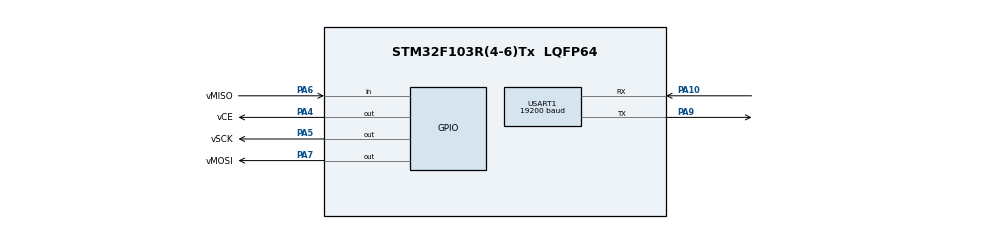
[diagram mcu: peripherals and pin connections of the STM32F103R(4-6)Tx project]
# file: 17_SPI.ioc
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Mcu.Family=STM32F1
Mcu.Name=STM32F103R(4-6)Tx
Mcu.Package=LQFP64
NVIC.PriorityGroup=NVIC_PRIORITYGROUP_4
NVIC.USART1_IRQn=true\:0\:0\:false\:false\:true\:true\:true\:true
PA10.Mode=Asynchronous
PA10.Signal=USART1_RX
PA4.GPIO_Label=vCE
PA4.GPIO_ModeDefaultOutputPP=GPIO_MODE_OUTPUT_PP
PA4.GPIO_PuPd=GPIO_PULLDOWN
PA4.Signal=GPIO_Output
PA5.GPIO_Label=vSCK
PA5.GPIO_ModeDefaultOutputPP=GPIO_MODE_OUTPUT_OD
PA5.GPIO_PuPd=GPIO_PULLUP
PA5.GPIO_Speed=GPIO_SPEED_FREQ_HIGH
PA5.PinState=GPIO_PIN_SET
PA5.Signal=GPIO_Output
PA6.GPIO_Label=vMISO
PA6.GPIO_Mode=GPIO_MODE_INPUT
PA6.GPIO_PuPd=GPIO_PULLUP
PA6.Signal=GPIO_Input
PA7.GPIO_Label=vMOSI
PA7.GPIO_ModeDefaultOutputPP=GPIO_MODE_OUTPUT_OD
PA7.GPIO_PuPd=GPIO_PULLUP
PA7.GPIO_Speed=GPIO_SPEED_FREQ_HIGH
PA7.PinState=GPIO_PIN_SET
PA7.Signal=GPIO_Output
PA9.Mode=Asynchronous
PA9.Signal=USART1_TX
ProjectManager.HeapSize=0x200
ProjectManager.StackSize=0x400
ProjectManager.TargetToolchain=MDK-ARM V5.32
RCC.APB1Freq_Value=8000000
RCC.APB2Freq_Value=8000000
USART1.BaudRate=19200
USART1.VirtualMode=VM_ASYNC
VP_SYS_VS_ND.Mode=No_Debug
board=custom

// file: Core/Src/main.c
/* USER CODE BEGIN Header */
/**
  ******************************************************************************
  * @file           : main.c
  * @brief          : Main program body
  ******************************************************************************
  * @attention
  *
  * Copyright (c) 2022 STMicroelectronics.
  * All rights reserved.
  *
  * This software is licensed under terms that can be found in the LICENSE file
  * in the root directory of this software component.
  * If no LICENSE file comes with this software, it is provided AS-IS.
  *
  ******************************************************************************
  */
/* USER CODE END Header */
#include "main.h"
#include "usart.h"
#include "gpio.h"

/* USER CODE BEGIN Includes */
#include "stdio.h"	//引入输入输出标准库
#include "vSPI.h"		//引入自定义头文件
#include "TC72.h"
/* USER CODE END Includes */

void SystemClock_Config(void);

int main(void)
{
  /* USER CODE BEGIN 1 */
	float t;
	char str1[] = "Temperature:";
	char str2[10];		//存放温度字符串
  /* USER CODE END 1 */

  /* MCU Configuration--------------------------------------------------------*/

  /* Reset of all peripherals, Initializes the Flash interface and the Systick. */
  HAL_Init();

  /* Configure the system clock */
  SystemClock_Config();

  /* Initialize all configured peripherals */
  MX_GPIO_Init();
  MX_USART1_UART_Init();

  /* Infinite loop */
  /* USER CODE BEGIN WHILE */
  while (1)
  {
		HAL_UART_Transmit(&huart1, (uint8_t *)str1, 12, 12);		//串口发送str1
		TC72_Convert(_TC72_OnceCnv);		//单次转化指令
		HAL_Delay(100);
		t = TC72_TemperatureRd();		//读传感器温度
		sprintf(str2, "%f", t);		//将温度t由浮点型转化为字符串并存入数组str2
		HAL_UART_Transmit(&huart1, (uint8_t *)str2, 7, 7);		//串口发送str2
		HAL_UART_Transmit(&huart1, (uint8_t *)&"\n\r", 2, 2);
		HAL_Delay(900);
    /* USER CODE END WHILE */

  }
}

void SystemClock_Config(void)
{
  RCC_OscInitTypeDef RCC_OscInitStruct = {0};
  RCC_ClkInitTypeDef RCC_ClkInitStruct = {0};

  /** Initializes the RCC Oscillators according to the specified parameters
  * in the RCC_OscInitTypeDef structure.
  */
  RCC_OscInitStruct.OscillatorType = RCC_OSCILLATORTYPE_HSI;
  RCC_OscInitStruct.HSIState = RCC_HSI_ON;
  RCC_OscInitStruct.HSICalibrationValue = RCC_HSICALIBRATION_DEFAULT;
  RCC_OscInitStruct.PLL.PLLState = RCC_PLL_NONE;
  if (HAL_RCC_OscConfig(&RCC_OscInitStruct) != HAL_OK)
  {
    Error_Handler();
  }

  /** Initializes the CPU, AHB and APB buses clocks
  */
  RCC_ClkInitStruct.ClockType = RCC_CLOCKTYPE_HCLK|RCC_CLOCKTYPE_SYSCLK
                              |RCC_CLOCKTYPE_PCLK1|RCC_CLOCKTYPE_PCLK2;
  RCC_ClkInitStruct.SYSCLKSource = RCC_SYSCLKSOURCE_HSI;
  RCC_ClkInitStruct.AHBCLKDivider = RCC_SYSCLK_DIV1;
  RCC_ClkInitStruct.APB1CLKDivider = RCC_HCLK_DIV1;
  RCC_ClkInitStruct.APB2CLKDivider = RCC_HCLK_DIV1;

  if (HAL_RCC_ClockConfig(&RCC_ClkInitStruct, FLASH_LATENCY_0) != HAL_OK)
  {
    Error_Handler();
  }
}

void Error_Handler(void)
{
  __disable_irq();
  while (1)
  {
  }
}
